# APM32F411 register map
Vendor: Geehy; File version: 2024.11.05
CPU: CM4 r1p0, little endian, 3 interrupt priority bits
Registers are 32-bit, read-write, reset 0x0 unless marked. A register's access mark holds for its fields unless they carry their own. Offsets are from the block's base; [hi:lo] are bit positions; {n}, {i} and the like mark numbered series; 'fields as' and 'values as' point back to an identical list.

## IWDT — Independent watchdog
Base 0x40003000
0x00 KEY wo
  [15:0] KEY — Key value (write only, read 0000h)
0x04 PSC — Prescaler register
  [2:0] PSC — Prescaler divider
0x08 CNTRLD reset 0xFFF — Reload register
  [11:0] CNTRLD — Watchdog counter reload value
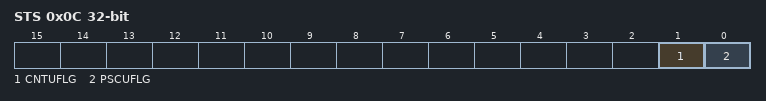
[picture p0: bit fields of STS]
0x0C STS ro — Status register
  [1] CNTUFLG — Watchdog counter reload value update
  [0] PSCUFLG — Watchdog prescaler value update

## OTG_FS_HOST — USB on the go full speed
Base 0x50000400
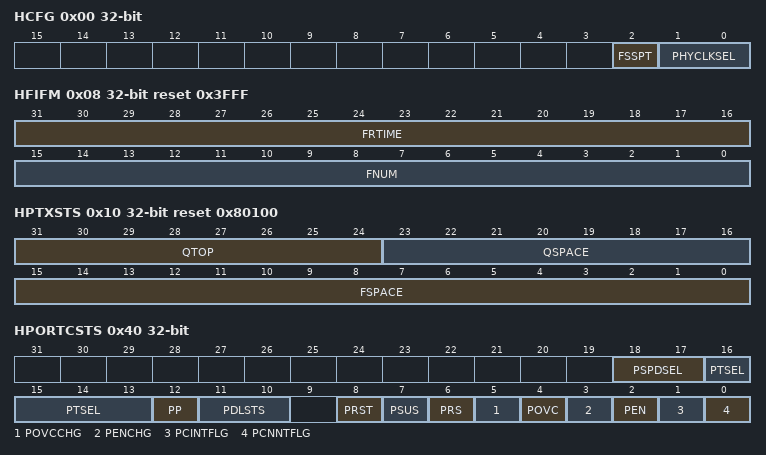
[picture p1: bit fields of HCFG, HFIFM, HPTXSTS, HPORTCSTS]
0x00 HCFG access per field — OTG_FS host configuration register (OTG_FS_HCFG)
  [2] FSSPT ro — FS- and LS-only support
  [1:0] PHYCLKSEL rw — FS/LS PHY clock select
0x04 HFIVL reset 0xEA60 — OTG_FS Host frame interval register
  [15:0] FIVL — Frame interval
0x08 HFIFM ro reset 0x3FFF — OTG_FS host frame number/frame time remaining register (OTG_FS_HFNUM)
  [31:16] FRTIME — Frame time remaining
  [15:0] FNUM — Frame number
0x10 HPTXSTS access per field reset 0x80100 — OTG_FS_Host periodic transmit FIFO/queue status register (OTG_FS_HPTXSTS)
  [31:24] QTOP ro — Top of the periodic transmit request queue
  [23:16] QSPACE ro — Periodic transmit request queue space available
  [15:0] FSPACE rw — Periodic transmit data FIFO space available
0x14 HACHINT ro — OTG_FS Host all channels interrupt register
  [15:0] ACHINT — Channel interrupts
0x18 HACHIMASK — OTG_FS host all channels interrupt mask register
  [15:0] ACHIMASK — Channel interrupt mask
0x40 HPORTCSTS access per field — OTG_FS host port control and status register (OTG_FS_HPRT)
  [18:17] PSPDSEL ro — Port speed
  [16:13] PTSEL rw — Port test control
  [12] PP rw — Port power
  [11:10] PDLSTS ro — Port line status
  [8] PRST rw — Port reset
  [7] PSUS rw — Port suspend
  [6] PRS rw — Port resume
  [5] POVCCHG rw — Port overcurrent change
  [4] POVC ro — Port overcurrent active
  [3] PENCHG rw — Port enable/disable change
  [2] PEN rw — Port enable
  [1] PCINTFLG rw — Port connect detected
  [0] PCNNTFLG ro — Port connect status
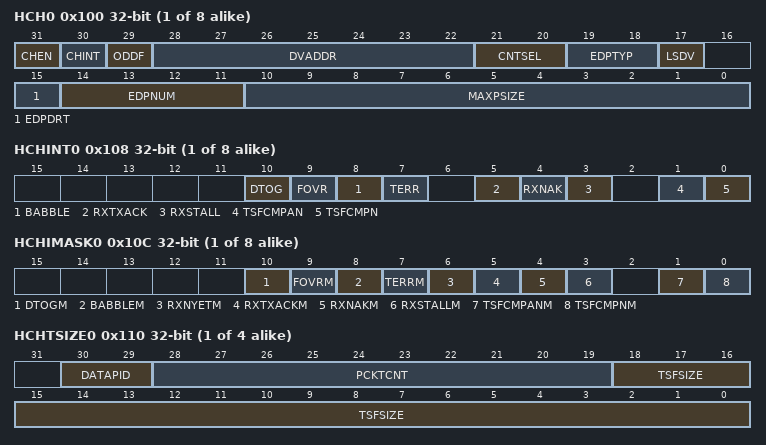
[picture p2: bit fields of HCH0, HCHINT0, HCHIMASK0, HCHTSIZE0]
{0x100+0x20*i} HCH{i} (i=0..7) — OTG_FS host channel-{i} characteristics register (OTG_FS_HCCHAR{i})
  [31] CHEN — Channel enable
  [30] CHINT — Channel disable
  [29] ODDF — Odd frame
  [28:22] DVADDR — Device address
  [21:20] CNTSEL — Multicount
  [19:18] EDPTYP — Endpoint type
  [17] LSDV — Low-speed device
  [15] EDPDRT — Endpoint direction
  [14:11] EDPNUM — Endpoint number
  [10:0] MAXPSIZE — Maximum packet size
{0x108+0x20*i} HCHINT{i} (i=0..7) — OTG_FS host channel-{i} interrupt register (OTG_FS_HCINT{i})
  [10] DTOG — Data toggle error
  [9] FOVR — Frame overrun
  [8] BABBLE — Babble error
  [7] TERR — Transaction error
  [5] RXTXACK — ACK response received/transmitted interrupt
  [4] RXNAK — NAK response received interrupt
  [3] RXSTALL — STALL response received interrupt
  [1] TSFCMPAN — Channel halted
  [0] TSFCMPN — Transfer completed
{0x10C+0x20*i} HCHIMASK{i} (i=0..7) — OTG_FS host channel-{i} mask register (OTG_FS_HCINTMSK{i})
  [10] DTOGM — Data toggle error mask
  [9] FOVRM — Frame overrun mask
  [8] BABBLEM — Babble error mask
  [7] TERRM — Transaction error mask
  [6] RXNYETM — response received interrupt mask
  [5] RXTXACKM — ACK response received/transmitted interrupt mask
  [4] RXNAKM — NAK response received interrupt mask
  [3] RXSTALLM — STALL response received interrupt mask
  [1] TSFCMPANM — Channel halted mask
  [0] TSFCMPNM — Transfer completed mask
{0x110+0x20*i} HCHTSIZE{i} (i=0..3) — OTG_FS host channel-{i} transfer size register
  [30:29] DATAPID
  [28:19] PCKTCNT — Packet count
  [18:0] TSFSIZE — Transfer size
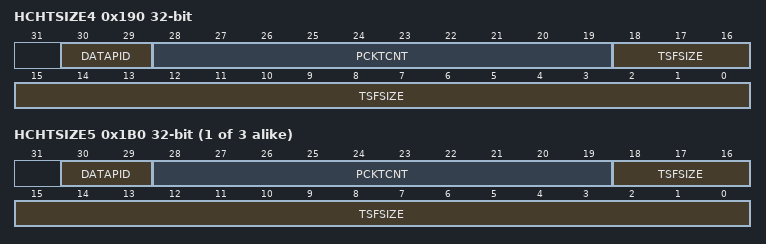
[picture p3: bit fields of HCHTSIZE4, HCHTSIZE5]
0x190 HCHTSIZE4 — OTG_FS host channel-x transfer size register
  fields as HCHTSIZE0
{0x110+0x20*i} HCHTSIZE{i} (i=5..7) — OTG_FS host channel-{i} transfer size register
  fields as HCHTSIZE0
